# STM32L0x0 register map
File version: 1.3
CPU: CM0+ r0p0, little endian, MPU, no FPU, 2 interrupt priority bits
Registers are 32-bit, read-write, reset 0x0 unless marked. A register's access mark holds for its fields unless they carry their own. Offsets are from the block's base; [hi:lo] are bit positions.

## FLASH
Base 0x40022000
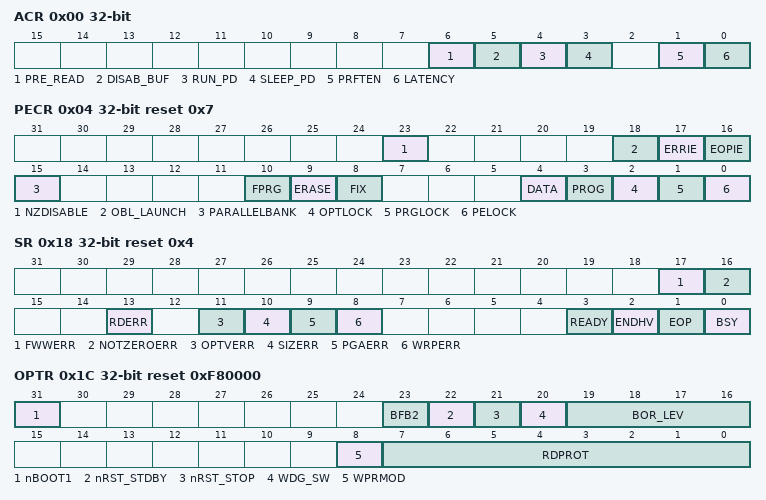
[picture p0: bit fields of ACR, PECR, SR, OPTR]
0x00 ACR — Access control register
  [6] PRE_READ — Pre-read data address
    0=Disabled (The pre-read is disabled); 1=Enabled (The pre-read is enabled)
  [5] DISAB_BUF — Disable Buffer
    0=Enabled (The buffers are enabled); 1=Disabled (The buffers are disabled)
  [4] RUN_PD — Flash mode during Run
    0=NVMIdleMode (When the device is in Run mode, the NVM is in Idle mode); 1=NVMPwrDownMode (When the device is in Run mode, the NVM is in power-down mode)
  [3] SLEEP_PD — Flash mode during Sleep
    0=NVMIdleMode (When the device is in Sleep mode, the NVM is in Idle mode); 1=NVMPwrDownMode (When the device is in Sleep mode, the NVM is in power-down mode)
  [1] PRFTEN — Prefetch enable
    0=Disabled (Prefetch is disabled); 1=Enabled (Prefetch is enabled)
  [0] LATENCY
    0=WS0 (Zero wait state is used to read a word in the NVM); 1=WS1 (One wait state is used to read a word in the NVM)
0x04 PECR reset 0x7 — Program/erase control register
  [23] NZDISABLE — Non-Zero check notification disable
  [18] OBL_LAUNCH — Launch the option byte loading
    on read: 0=Complete (Option byte loaded); 1=NotComplete (Option byte loading to be done) | on write: 1=Reload option byte
  [17] ERRIE — Error interrupt enable
    0=Disabled (Error interrupt disable); 1=Enabled (Error interrupt enable)
  [16] EOPIE — End of programming interrupt enable
    0=Disabled (End of program interrupt disable); 1=Enabled (End of program interrupt enable)
  [15] PARALLELBANK — Parallel bank mode
    0=Disabled (Parallel bank mode disabled); 1=Enabled (Parallel bank mode enabled)
  [10] FPRG — Half Page/Double Word programming mode
    0=Disabled (Half Page programming disabled); 1=Enabled (Half Page programming enabled)
  [9] ERASE — Page or Double Word erase mode
    0=No erase operation requested; 1=Erase operation requested
  [8] FIX — Fixed time data write for Byte, Half Word and Word programming
    0=AutoErase (An erase phase is automatically performed); 1=PrelimErase (The program operation is always performed with a preliminary erase)
  [4] DATA — Data EEPROM selection
    0=NotSelected (Data EEPROM not selected); 1=Selected (Data memory selected)
  [3] PROG — Program memory selection
    0=NotSelected (The Flash program memory is not selected); 1=Selected (The Flash program memory is selected)
  [2] OPTLOCK — Option bytes block lock
    0=Unlocked (The write and erase operations in the Option bytes area are disabled); 1=Locked (The write and erase operations in the Option bytes area are enabled)
  [1] PRGLOCK — Program memory lock
    0=Unlocked (The write and erase operations in the Flash program memory are disabled); 1=Locked (The write and erase operations in the Flash program memory are enabled)
  [0] PELOCK — FLASH_PECR and data EEPROM lock
    0=Unlocked (The FLASH_PECR register is unlocked); 1=Locked (The FLASH_PECR register is locked and no write/erase operation can start)
0x08 PDKEYR wo — Power down key register
  [31:0] PDKEYR — RUN_PD in FLASH_ACR key
0x0C PEKEYR wo — Program/erase key register
  [31:0] PEKEYR — FLASH_PEC and data EEPROM key
0x10 PRGKEYR wo — Program memory key register
  [31:0] PRGKEYR — Program memory key
0x14 OPTKEYR wo — Option byte key register
  [31:0] OPTKEYR — Option byte key
0x18 SR access per field reset 0x4 — Status register
  [17] FWWERR rw
    on read: 0=NoError (No write/erase operation aborted to perform a fetch); 1=Error (A write/erase operation aborted to perform a fetch) | on write: 1=Clear the flag
  [16] NOTZEROERR rw
    on read: 0=NoEvent (The write operation is done in an erased region or the memory interface can apply an erase before a write); 1=Event (The write operation is attempting to write to a not-erased region and the memory interface cannot apply an erase before a write) | on write: 1=Clear the flag
  [13] RDERR rw
    on read: 0=NoError (No read protection error happened.); 1=Error (One read protection error happened) | on write: 1=Clear the flag
  [11] OPTVERR rw — Option validity error
    on read: 0=No error happened during the Option bytes loading; 1=Error (One or more errors happened during the Option bytes loading) | on write: 1=Clear the flag
  [10] SIZERR rw — Size error
    on read: 0=NoError (No size error happened); 1=Error (One size error happened) | on write: 1=Clear the flag
  [9] PGAERR rw — Programming alignment error
    on read: 0=NoError (No alignment error happened); 1=Error (One alignment error happened) | on write: 1=Clear the flag
  [8] WRPERR rw — Write protected error
    on read: 0=NoError (No protection error happened); 1=Error (One protection error happened) | on write: 1=Clear the flag
  [3] READY ro — Flash memory module ready after low power mode
    0=NotReady (The NVM is not ready); 1=Ready (The NVM is ready)
  [2] ENDHV ro — End of high voltage
    0=Active (High voltage is executing a write/erase operation in the NVM); 1=Inactive (High voltage is off, no write/erase operation is ongoing)
  [1] EOP ro — End of operation
    0=NoEvent (No EOP operation occurred); 1=Event (An EOP event occurred)
  [0] BSY ro — Write/erase operations in progress
    0=Inactive (No write/erase operation is in progress); 1=Active (No write/erase operation is in progress)
0x1C OPTR ro reset 0xF80000 — Option byte register
  [31] nBOOT1
  [23] BFB2
  [22] nRST_STDBY
  [21] nRST_STOP
  [20] WDG_SW
  [19:16] BOR_LEV
    0=BOR_Off (This is the reset threshold level for the 1.45 V - 1.55 V voltage range (power-down only)); 1=BOR_Level1 (Reset threshold level for VBOR0 (around 1.8 V)); 2=BOR_Level2 (Reset threshold level for VBOR1 (around 2.0 V)); 3=BOR_Level3 (Reset threshold level for VBOR2 (around 2.5 V)); 4=BOR_Level4 (Reset threshold level for VBOR3 (around 2.7 V)); 5=BOR_Level5 (Reset threshold level for VBOR4 (around 3.0 V))
  [8] WPRMOD
    0=Disabled (PCROP disabled. The WRPROT bits are used as a write protection on a sector.); 1=Enabled (PCROP enabled. The WRPROT bits are used as a read protection on a sector.)
  [7:0] RDPROT — Read protection
    0=Level1; 170=Level0; 204=Level2
0x20 WRPROT1 ro — Write protection register
  [31:0] WRPROT1 — Write protection
0x80 WRPROT2 ro — Write protection register
  [15:0] WRPROT2 — Write protection
